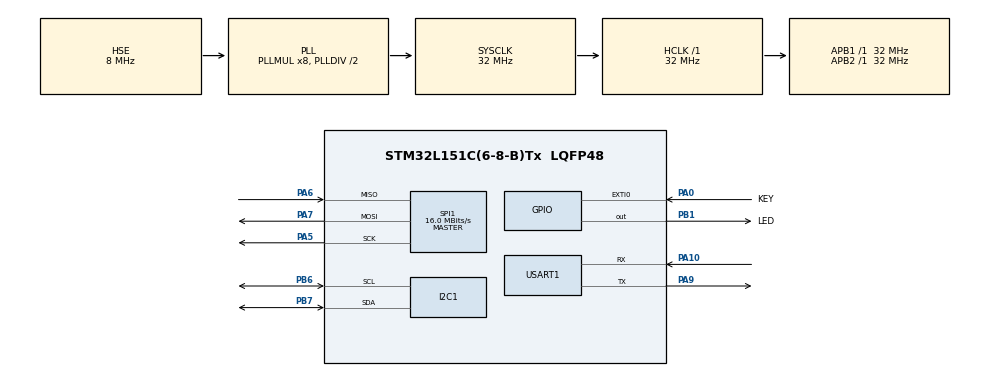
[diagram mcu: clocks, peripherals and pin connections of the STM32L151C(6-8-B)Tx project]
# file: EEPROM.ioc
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Mcu.Family=STM32L1
Mcu.Name=STM32L151C(6-8-B)Tx
Mcu.Package=LQFP48
NVIC.EXTI0_IRQn=true\:2\:0\:true
NVIC.PriorityGroup=NVIC_PRIORITYGROUP_4
NVIC.USART1_IRQn=true\:1\:0\:true
PA0-WKUP1.GPIO_Label=KEY
PA0-WKUP1.GPIO_ModeDefaultEXTI=GPIO_MODE_IT_RISING
PA0-WKUP1.GPIO_PuPd=GPIO_PULLDOWN
PA0-WKUP1.Signal=GPXTI0
PA10.Mode=Asynchronous
PA10.Signal=USART1_RX
PA13.Mode=Serial-Wire
PA13.Signal=SYS_JTMS-SWDIO
PA14.Mode=Serial-Wire
PA14.Signal=SYS_JTCK-SWCLK
PA5.Mode=Full_Duplex_Master
PA5.Signal=SPI1_SCK
PA6.Mode=Full_Duplex_Master
PA6.Signal=SPI1_MISO
PA7.Mode=Full_Duplex_Master
PA7.Signal=SPI1_MOSI
PA9.Mode=Asynchronous
PA9.Signal=USART1_TX
PB1.GPIO_Label=LED
PB1.GPIO_PuPd=GPIO_PULLUP
PB1.Signal=GPIO_Output
PB6.Mode=I2C
PB6.Signal=I2C1_SCL
PB7.Mode=I2C
PB7.Signal=I2C1_SDA
PC14-OSC32_IN.Mode=LSE-External-Oscillator
PC14-OSC32_IN.Signal=RCC_OSC32_IN
PC15-OSC32_OUT.Mode=LSE-External-Oscillator
PC15-OSC32_OUT.Signal=RCC_OSC32_OUT
PH0-OSC_IN.Mode=HSE-External-Oscillator
PH0-OSC_IN.Signal=RCC_OSC_IN
PH1-OSC_OUT.Mode=HSE-External-Oscillator
PH1-OSC_OUT.Signal=RCC_OSC_OUT
ProjectManager.HeapSize=0x400
ProjectManager.StackSize=0x200
ProjectManager.TargetToolchain=MDK-ARM V5
RCC.AHBFreq_Value=32000000
RCC.APB1Freq_Value=32000000
RCC.APB1TimFreq_Value=32000000
RCC.APB2Freq_Value=32000000
RCC.APB2TimFreq_Value=32000000
RCC.HCLKFreq_Value=32000000
RCC.HSE_VALUE=8000000
RCC.HSI_VALUE=16000000
RCC.MSI_VALUE=2097000
RCC.PLLMUL=RCC_PLL_MUL8
RCC.PLLSourceVirtual=RCC_PLLSOURCE_HSE
RCC.SYSCLKFreq_VALUE=32000000
RCC.SYSCLKSource=RCC_SYSCLKSOURCE_PLLCLK
RCC.USBOutput=32000000
RCC.VCOOutputFreq_Value=64000000
SPI1.BaudRatePrescaler=SPI_BAUDRATEPRESCALER_2
SPI1.CalculateBaudRate=16.0 MBits/s
SPI1.Mode=SPI_MODE_MASTER
board=EEPROM

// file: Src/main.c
/**
  ******************************************************************************
  * File Name          : main.c
  * Description        : Main program body
  ******************************************************************************
  *
  * COPYRIGHT(c) 2016 STMicroelectronics
  *
  * Redistribution and use in source and binary forms, with or without modification,
  * are permitted provided that the following conditions are met:
  *   1. Redistributions of source code must retain the above copyright notice,
  *      this list of conditions and the following disclaimer.
  *   2. Redistributions in binary form must reproduce the above copyright notice,
  *      this list of conditions and the following disclaimer in the documentation
  *      and/or other materials provided with the distribution.
  *   3. Neither the name of STMicroelectronics nor the names of its contributors
  *      may be used to endorse or promote products derived from this software
  *      without specific prior written permission.
  *
  * THIS SOFTWARE IS PROVIDED BY THE COPYRIGHT HOLDERS AND CONTRIBUTORS "AS IS"
  * AND ANY EXPRESS OR IMPLIED WARRANTIES, INCLUDING, BUT NOT LIMITED TO, THE
  * IMPLIED WARRANTIES OF MERCHANTABILITY AND FITNESS FOR A PARTICULAR PURPOSE ARE
  * DISCLAIMED. IN NO EVENT SHALL THE COPYRIGHT HOLDER OR CONTRIBUTORS BE LIABLE
  * FOR ANY DIRECT, INDIRECT, INCIDENTAL, SPECIAL, EXEMPLARY, OR CONSEQUENTIAL
  * DAMAGES (INCLUDING, BUT NOT LIMITED TO, PROCUREMENT OF SUBSTITUTE GOODS OR
  * SERVICES; LOSS OF USE, DATA, OR PROFITS; OR BUSINESS INTERRUPTION) HOWEVER
  * CAUSED AND ON ANY THEORY OF LIABILITY, WHETHER IN CONTRACT, STRICT LIABILITY,
  * OR TORT (INCLUDING NEGLIGENCE OR OTHERWISE) ARISING IN ANY WAY OUT OF THE USE
  * OF THIS SOFTWARE, EVEN IF ADVISED OF THE POSSIBILITY OF SUCH DAMAGE.
  *
  ******************************************************************************
  */
#include "stm32l1xx_hal.h"
#include "i2c.h"
#include "spi.h"
#include "usart.h"
#include "gpio.h"

/* USER CODE BEGIN Includes */
#include "BSP_drive.h"
/* USER CODE END Includes */

/* USER CODE BEGIN PV */
/* Private variables ---------------------------------------------------------*/

/* USER CODE END PV */

void SystemClock_Config(void);

/* USER CODE BEGIN PFP */
/* Private function prototypes -----------------------------------------------*/

/* USER CODE END PFP */

/* USER CODE BEGIN 0 */
uint8_t str1[16] = "hello world! 0";
uint8_t str2[16] ={0};
/* USER CODE END 0 */

int main(void)
{

  /* USER CODE BEGIN 1 */
  uint8_t x=0;
  /* USER CODE END 1 */

  /* MCU Configuration----------------------------------------------------------*/

  /* Reset of all peripherals, Initializes the Flash interface and the Systick. */
  HAL_Init();

  /* Configure the system clock */
  SystemClock_Config();

  /* Initialize all configured peripherals */
  MX_GPIO_Init();
  MX_I2C1_Init();
  MX_SPI1_Init();
  MX_USART1_UART_Init();

  /* USER CODE BEGIN 2 */
	SeachI2cDev();
  /* USER CODE END 2 */

  /* Infinite loop */
  /* USER CODE BEGIN WHILE */
  while (1)
  {
	str1[13] = x+0x30;

	// I2C_MEMADD_SIZE_16BIT: AT24C32 16BIT of internal memory address
	HAL_I2C_Mem_Write(&hi2c1,0xA0, 0, I2C_MEMADD_SIZE_16BIT ,str1, 16,200);

	HAL_Delay(500);
	LED_TOG;

	HAL_I2C_Mem_Read(&hi2c1,0xA0, 0, I2C_MEMADD_SIZE_16BIT, str2, 16, 200);
	printf("%s\r\n",str2);

	x++;
	if (x==10) x=0;

  /* USER CODE END WHILE */

  }

}

/** System Clock Configuration
*/
void SystemClock_Config(void)
{

  RCC_OscInitTypeDef RCC_OscInitStruct;
  RCC_ClkInitTypeDef RCC_ClkInitStruct;

  __PWR_CLK_ENABLE();

  __HAL_PWR_VOLTAGESCALING_CONFIG(PWR_REGULATOR_VOLTAGE_SCALE1);

  RCC_OscInitStruct.OscillatorType = RCC_OSCILLATORTYPE_HSE;
  RCC_OscInitStruct.HSEState = RCC_HSE_ON;
  RCC_OscInitStruct.PLL.PLLState = RCC_PLL_ON;
  RCC_OscInitStruct.PLL.PLLSource = RCC_PLLSOURCE_HSE;
  RCC_OscInitStruct.PLL.PLLMUL = RCC_PLL_MUL8;
  RCC_OscInitStruct.PLL.PLLDIV = RCC_PLL_DIV2;
  HAL_RCC_OscConfig(&RCC_OscInitStruct);

  RCC_ClkInitStruct.ClockType = RCC_CLOCKTYPE_HCLK|RCC_CLOCKTYPE_SYSCLK
                              |RCC_CLOCKTYPE_PCLK1|RCC_CLOCKTYPE_PCLK2;
  RCC_ClkInitStruct.SYSCLKSource = RCC_SYSCLKSOURCE_PLLCLK;
  RCC_ClkInitStruct.AHBCLKDivider = RCC_SYSCLK_DIV1;
  RCC_ClkInitStruct.APB1CLKDivider = RCC_HCLK_DIV1;
  RCC_ClkInitStruct.APB2CLKDivider = RCC_HCLK_DIV1;
  HAL_RCC_ClockConfig(&RCC_ClkInitStruct, FLASH_LATENCY_1);

  HAL_SYSTICK_Config(HAL_RCC_GetHCLKFreq()/1000);

  HAL_SYSTICK_CLKSourceConfig(SYSTICK_CLKSOURCE_HCLK);

  /* SysTick_IRQn interrupt configuration */
  HAL_NVIC_SetPriority(SysTick_IRQn, 0, 0);
}

/************************ (C) COPYRIGHT STMicroelectronics *****END OF FILE****/
